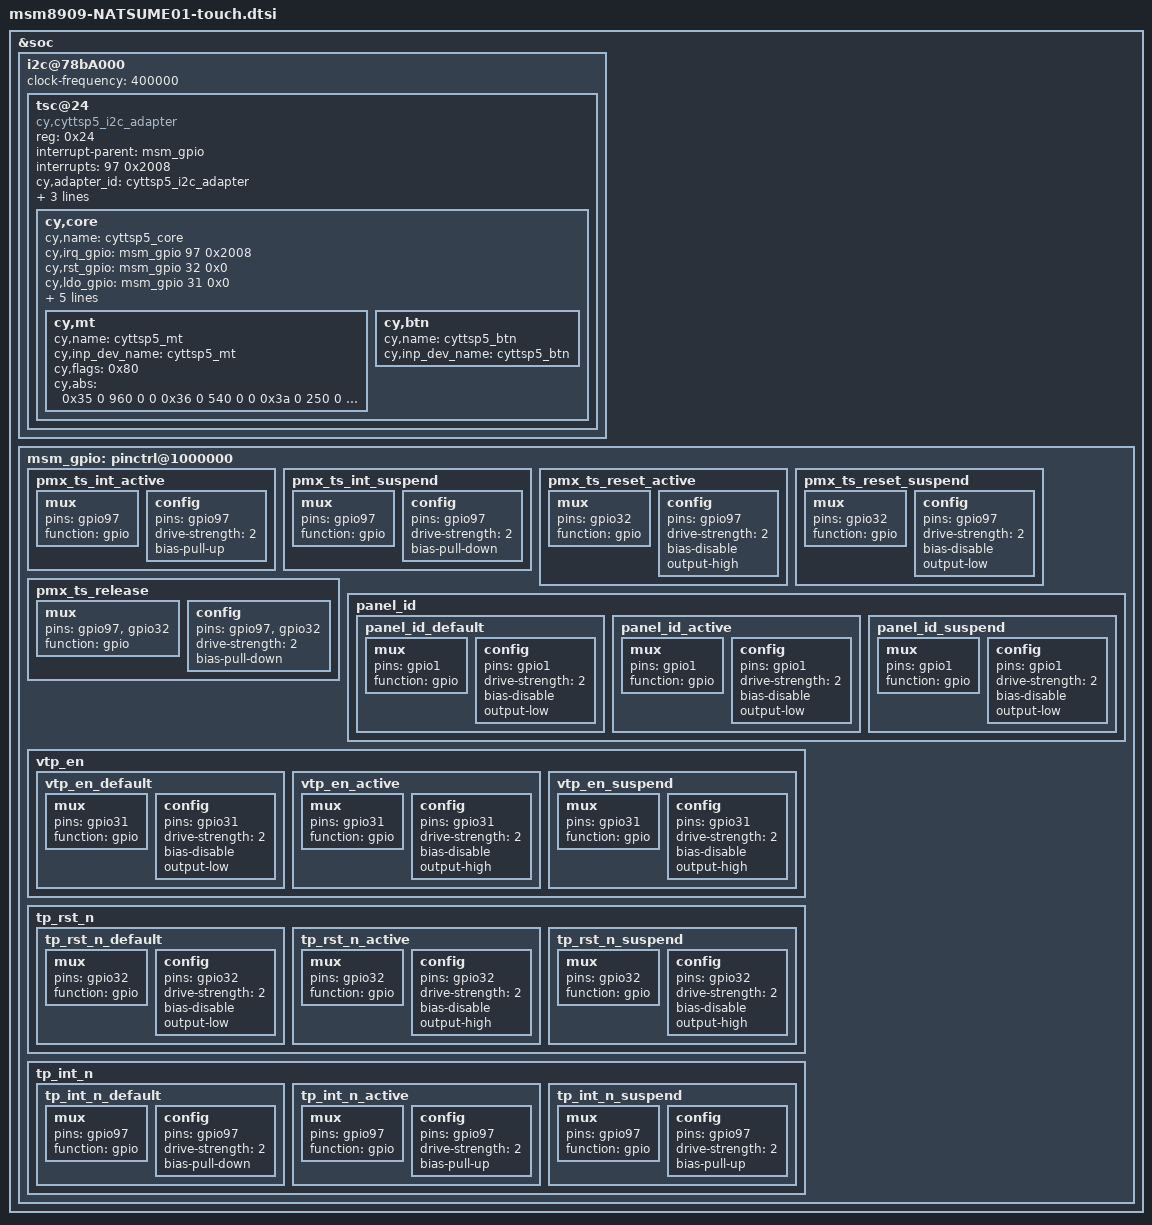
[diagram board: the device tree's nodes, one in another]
/*
 * This software is contributed or developed by KYOCERA Corporation.
 * (C) 2019 KYOCERA Corporation
 *
 * This program is free software; you can redistribute it and/or modify
 * it under the terms of the GNU General Public License version 2 and
 * only version 2 as published by the Free Software Foundation.
 *
 * This program is distributed in the hope that it will be useful,
 * but WITHOUT ANY WARRANTY; without even the implied warranty of
 * MERCHANTABILITY or FITNESS FOR A PARTICULAR PURPOSE.  See the
 * GNU General Public License for more details.
 */

&soc {
	i2c@78bA000 { /* BLSP1 QUP6 */
		clock-frequency = <400000>;

		tsc@24 {
			compatible = "cy,cyttsp5_i2c_adapter";
			reg = <0x24>;
			interrupt-parent = <&msm_gpio>;
			interrupts = <97 0x2008>;
			cy,adapter_id = "cyttsp5_i2c_adapter";

			vdd-supply = <&pm8916_l10>;
			pinctrl-names = "pmx_ts_active","pmx_ts_suspend";
			pinctrl-0 = <&tp_int_n_active>;
			pinctrl-1 = <&tp_int_n_default>;

			cy,core {
				cy,name = "cyttsp5_core";

                cy,irq_gpio = <&msm_gpio 97 0x2008>;
                cy,rst_gpio = <&msm_gpio 32 0x0>;
                cy,ldo_gpio = <&msm_gpio 31 0x0>;

                cy,hid_desc_register = <1>;
                cy,flags = <5>;
                cy,easy_wakeup_gesture = <0>;
                cy,glove_valid = <0>;

                cy,btn_keys = <172>;/* KEY_HOMEPAGE */

                cy,mt {
                   cy,name = "cyttsp5_mt";
                   cy,inp_dev_name = "cyttsp5_mt";
                   cy,flags = <0x80>;
                   cy,abs =
                           <0x35 0 960 0 0
                           0x36 0 540 0 0
                           0x3a 0 250 0 0
                           0xffff 0 255 0 0
                           0x39 0 15 0 0
                           0x30 0 20 0 0
                           0x31 0 20 0 0
                           0x34 0xffffff81 127 0 0
                           0x19 0 255 0 0>;
                };
                cy,btn {
                   cy,name = "cyttsp5_btn";
                   cy,inp_dev_name = "cyttsp5_btn";
                };

           };
		};
	};
	
	msm_gpio: pinctrl@1000000 {
		pmx_ts_int_active:pmx_ts_int_active{
			mux {
				pins = "gpio97";
				function = "gpio";
			};

			config {
				pins = "gpio97";
				drive-strength = <2>;   /* 2 mA */
				bias-pull-up;     /* PULL DOWN */
			};
		};
		
		pmx_ts_int_suspend:pmx_ts_int_suspend{
			mux {
				pins = "gpio97";
				function = "gpio";
			};

			config {
				pins = "gpio97";
				drive-strength = <2>;   /* 2 mA */
				bias-pull-down;     /* PULL DOWN */
			};
		};
		
		pmx_ts_reset_active:pmx_ts_reset_active{
			mux {
				pins = "gpio32";
				function = "gpio";
			};

			config {
				pins = "gpio97";
				drive-strength = <2>;   /* 2 mA */
				bias-disable;           /* No PULL */
				output-high;
			};
		};
		
		pmx_ts_reset_suspend:pmx_ts_reset_suspend{
			mux {
				pins = "gpio32";
				function = "gpio";
			};

			config {
				pins = "gpio97";
				drive-strength = <2>;   /* 2 mA */
				bias-disable;           /* No PULL */
				output-low;
			};
		};
		
		pmx_ts_reset_suspend:pmx_ts_reset_suspend{
			mux {
				pins = "gpio32";
				function = "gpio";
			};

			config {
				pins = "gpio97";
				drive-strength = <2>;   /* 2 mA */
				bias-disable;           /* No PULL */
				output-low;
			};
		};
		
		pmx_ts_release:pmx_ts_release{
			mux {
				pins = "gpio97", "gpio32";
				function = "gpio";
			};

			config {
				pins = "gpio97", "gpio32";
				drive-strength = <2>;   /* 2 mA */
				bias-pull-down;     /* PULL DOWN */
			};
		};
		
		panel_id {
			panel_id_default:panel_id_default{
				mux {
					pins = "gpio1";
					function = "gpio";
				};

				config {
					pins = "gpio1";
					drive-strength = <2>;   /* 2 mA */
					bias-disable;           /* No PULL */
					output-low;
				};
			};
			
			panel_id_active:panel_id_active{
				mux {
					pins = "gpio1";
					function = "gpio";
				};

				config {
					pins = "gpio1";
					drive-strength = <2>;   /* 2 mA */
					bias-disable;           /* No PULL */
					output-low;
				};
			};
			
			panel_id_suspend:panel_id_suspend{
				mux {
					pins = "gpio1";
					function = "gpio";
				};

				config {
					pins = "gpio1";
					drive-strength = <2>;   /* 2 mA */
					bias-disable;           /* No PULL */
					output-low;
				};
			};
			
		};
		
		
		vtp_en {
			vtp_en_default:vtp_en_default{
				mux {
					pins = "gpio31";
					function = "gpio";
				};

				config {
					pins = "gpio31";
					drive-strength = <2>;   /* 2 mA */
					bias-disable;           /* No PULL */
					output-low;
				};
			};
			
			vtp_en_active:vtp_en_active{
				mux {
					pins = "gpio31";
					function = "gpio";
				};

				config {
					pins = "gpio31";
					drive-strength = <2>;   /* 2 mA */
					bias-disable;
					output-high;
				};
			};
			
			vtp_en_suspend:vtp_en_suspend{
				mux {
					pins = "gpio31";
					function = "gpio";
				};

				config {
					pins = "gpio31";
					drive-strength = <2>;   /* 2 mA */
					bias-disable;
					output-high;
				};
			};
		};
		
		tp_rst_n{
			tp_rst_n_default:tp_rst_n_default{
				mux {
					pins = "gpio32";
					function = "gpio";
				};

				config {
					pins = "gpio32";
					drive-strength = <2>;   /* 2 mA */
					bias-disable;           /* No PULL */
					output-low;
				};
			};
			
			tp_rst_n_active:tp_rst_n_active{
				mux {
					pins = "gpio32";
					function = "gpio";
				};

				config {
					pins = "gpio32";
					drive-strength = <2>;   /* 2 mA */
					bias-disable;           /* No PULL */
					output-high;
				};
			};
			
			
			tp_rst_n_suspend:tp_rst_n_suspend{
				mux {
					pins = "gpio32";
					function = "gpio";
				};

				config {
					pins = "gpio32";
					drive-strength = <2>;   /* 2 mA */
					bias-disable;           /* No PULL */
					output-high;
				};
			};
		};
		
		tp_int_n{
			tp_int_n_default:tp_int_n_default{
				mux {
					pins = "gpio97";
					function = "gpio";
				};

				config {
					pins = "gpio97";
					drive-strength = <2>;   /* 2 mA */
					bias-pull-down;
				};
			};
			
			tp_int_n_active:tp_int_n_active{
				mux {
					pins = "gpio97";
					function = "gpio";
				};

				config {
					pins = "gpio97";
					drive-strength = <2>;   /* 2 mA */
					bias-pull-up;
				};
			};
			
			tp_int_n_suspend:tp_int_n_suspend{
				mux {
					pins = "gpio97";
					function = "gpio";
				};

				config {
					pins = "gpio97";
					drive-strength = <2>;   /* 2 mA */
					bias-pull-up;
				};
			};
		};
	};
};


/*
&tlmm_pinmux {
	pmx_ts_int_active {
		qcom,pins = <&gp 97>;
		qcom,pin-func = <0>;
		qcom,num-grp-pins = <1>;
		label = "pmx_ts_int_active";

		ts_int_active: ts_int_active {
			drive-strength = <2>;
			bias-pull-up;
		};
	};

	pmx_ts_int_suspend {
		qcom,pins = <&gp 97>;
		qcom,pin-func = <0>;
		qcom,num-grp-pins = <1>;
		label = "pmx_ts_int_suspend";

		ts_int_suspend: ts_int_suspend {
			drive-strength = <2>;
			bias-pull-down;
		};
	};

	pmx_ts_reset_active {
		qcom,pins = <&gp 32>;
		qcom,pin-func = <0>;
		qcom,num-grp-pins = <1>;
		label = "pmx_ts_reset_active";

		ts_reset_active: ts_reset_active {
			drive-strength = <2>;
			bias-pull-up;
		};
	};

	pmx_ts_reset_suspend {
		qcom,pins = <&gp 32>;
		qcom,pin-func = <0>;
		qcom,num-grp-pins = <1>;
		label = "pmx_ts_reset_suspend";

		ts_reset_suspend: ts_reset_suspend {
			drive-strength = <2>;
			bias-pull-down;
		};
	};

	pmx_ts_release {
		qcom,pins = <&gp 97>, <&gp 32>;
		qcom,num-grp-pins = <2>;
		label = "pmx_ts_release";

		ts_release: ts_release {
			drive-strength = <2>;
			bias-pull-down;
		};
	};

	panel_id {
		qcom,pins = <&gp 1>;
		qcom,pin-func = <0>;
		qcom,num-grp-pins = <1>;
		label = "panel_id";
		panel_id_default: panel_id_default {
			drive-strength = <2>;
			bias-pull-down;
		};
		panel_id_active: panel_id_active {
			drive-strength = <2>;
			bias-pull-down;
		};
		panel_id_suspend: panel_id_suspend {
			drive-strength = <2>;
			bias-pull-down;
		};
	};

	vtp_en {
		qcom,pins = <&gp 31>;
		qcom,pin-func = <0>;
		qcom,num-grp-pins = <1>;
		label = "vtp_en";
		vtp_en_default: vtp_en_default {
			drive-strength = <2>;
			bias-disable;
			output-low;
		};
		vtp_en_active: vtp_en_active {
			drive-strength = <2>;
			bias-disable;
			output-high;
		};
		vtp_en_suspend: vtp_en_suspend {
			drive-strength = <2>;
			bias-disable;
			output-high;
		};
	};

	tp_rst_n {
		qcom,pins = <&gp 32>;
		qcom,pin-func = <0>;
		qcom,num-grp-pins = <1>;
		label = "tp_rst_n";
		tp_rst_n_default: tp_rst_n_default {
			drive-strength = <2>;
			bias-disable;
			output-low;
		};
		tp_rst_n_active: tp_rst_n_active {
			drive-strength = <2>;
			bias-disable;
			output-high;
		};
		tp_rst_n_suspend: tp_rst_n_suspend {
			drive-strength = <2>;
			bias-disable;
			output-high;
		};
	};

	tp_int_n {
		qcom,pins = <&gp 97>;
		qcom,pin-func = <0>;
		qcom,num-grp-pins = <1>;
		label = "tp_int_n";
		tp_int_n_default: tp_int_n_default {
			drive-strength = <2>;
			bias-pull-down;
		};
		tp_int_n_active: tp_int_n_active {
			drive-strength = <2>;
			bias-pull-up;
		};
		tp_int_n_suspend: tp_int_n_suspend {
			drive-strength = <2>;
			bias-pull-up;
		};
	};
};

*/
